VERSION ""

NS_ :

BS_:

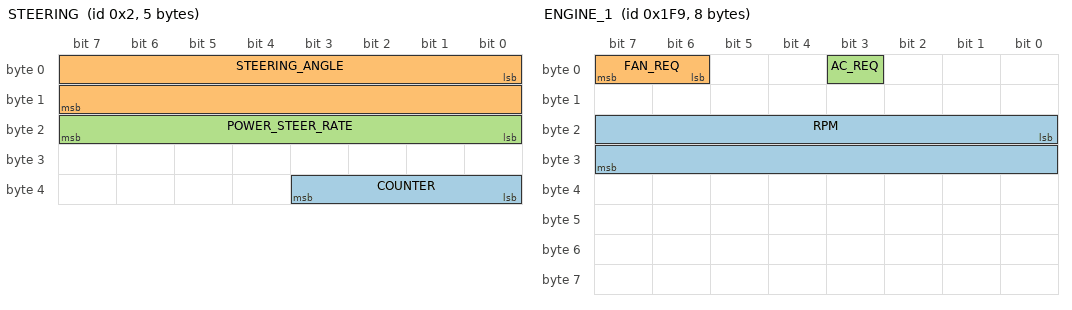
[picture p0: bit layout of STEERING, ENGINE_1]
BO_ 2 STEERING: 5 XXX
 SG_ COUNTER : 35|4@0+ (1,0) [0|255] "" XXX
 SG_ STEERING_ANGLE : 0|16@1- (0.1,0) [0|65535] "deg" XXX
 SG_ POWER_STEER_RATE : 23|8@0+ (1,0) [0|255] "" XXX

BO_ 505 ENGINE_1: 8 XXX
 SG_ RPM : 16|16@1+ (0.125,0) [0|45000] "R/min" XXX
 SG_ FAN_REQ : 6|2@1+ (1,0) [0|3] "" XXX
 SG_ AC_REQ : 3|1@1+ (1,0) [0|1] "" XXX

BO_ 561 ENGINE_2: 8 XXX
 SG_ Pedal_position : 16|8@1+ (0.5,0) [0|200] "%" XXX

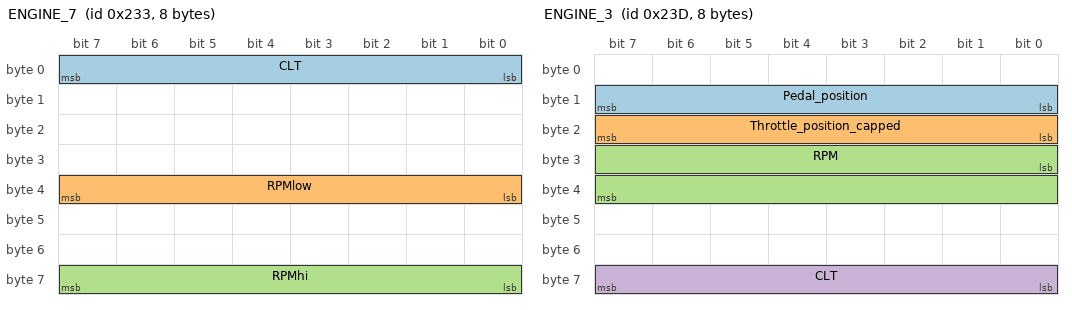
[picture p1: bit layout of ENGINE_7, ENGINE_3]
BO_ 563 ENGINE_7: 8 XXX
 SG_ CLT : 0|8@1+ (0.366666,0) [0|255] "C" XXX
 SG_ RPMlow : 32|8@1+ (3.15,0) [0|45000] "R/min" XXX
 SG_ RPMhi : 56|8@1+ (3.15,0) [0|45000] "R/min" XXX

BO_ 573 ENGINE_3: 8 XXX
 SG_ Pedal_position : 8|8@1+ (0.392,0) [0|255] "%" XXX
 SG_ Throttle_position_capped : 16|8@1+ (0.392,0) [0|255] "%" XXX
 SG_ RPM : 24|16@1+ (3.15,0) [0|45000] "R/min" XXX
 SG_ CLT : 56|8@1+ (0.366666,0) [0|255] "C" XXX

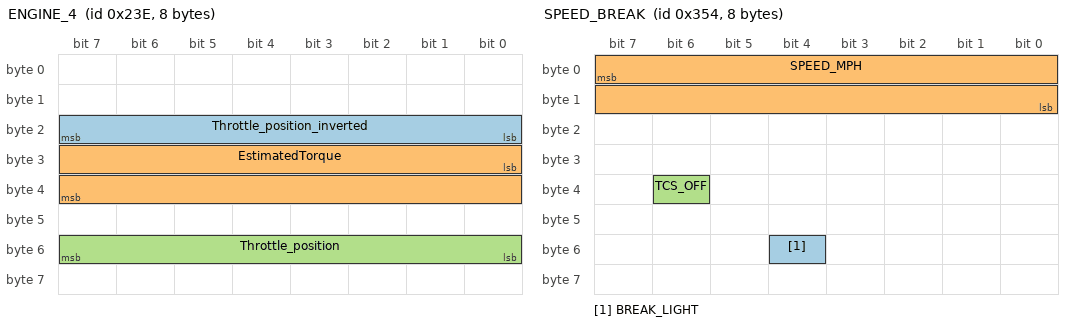
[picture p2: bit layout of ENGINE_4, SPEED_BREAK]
BO_ 574 ENGINE_4: 8 XXX
 SG_ Throttle_position_inverted : 16|8@1+ (0.392,0) [0|255] "%" XXX
 SG_ EstimatedTorque : 24|16@1+ (0.1,0) [0|45000] "nM" XXX
 SG_ Throttle_position : 48|8@1+ (0.392,0) [0|255] "%" XXX

BO_ 595 TCU_1: 8 XXX
 SG_ SHAFT_1_SPEED : 32|16@1+ (1,0) [0|45000] "r/min" XXX
 SG_ SHAFT_2_SPEED : 48|16@1+ (1,0) [0|45000] "r/min" XXX

BO_ 640 SPEED: 8 XXX
 SG_ SPEED : 32|16@1+ (0.01,0) [0|45000] "km/h" XXX

BO_ 644 ABS_1: 8 XXX
 SG_ WHEEL_1 : 0|16@1+ (0.01,0) [0|45000] "km/h" XXX
 SG_ WHEEL_2 : 15|16@1+ (0.01,0) [0|45000] "km/h" XXX

BO_ 645 ABS_2: 8 XXX
 SG_ WHEEL_3 : 0|16@1+ (0.01,0) [0|45000] "km/h" XXX
 SG_ WHEEL_4 : 15|16@1+ (0.01,0) [0|45000] "km/h" XXX

BO_ 852 SPEED_BREAK: 8 XXX
 SG_ BREAK_LIGHT : 52|1@0+ (1,0) [0|3] "" XXX
 SG_ SPEED_MPH : 7|16@0+ (0.0066,0) [0|65535] "mph" XXX
 SG_ TCS_OFF : 38|1@0+ (1,0) [0|255] "" XXX

BO_ 861 BCM: 8 XXX

BO_ 1361 ENGINE_5: 8 XXX
 SG_ CLT : 0|8@1+ (1,-45) [-45|150] "" XXX

BO_ 1408 ENGINE_6: 8 XXX
 SG_ RPM : 7|16@0+ (1.5,0) [0|65535] "" XXX
 SG_ OIL_TEMP : 32|8@1+ (1,-40) [-40|150] "" XXX

BU_: XXX

CM_ 272 "Alternative LKAS message, used on cars such as 2023 Ioniq 6, 2nd gen Kona. Matches LKAS except size is 32 bytes";
CM_ 676 "Contains signals with detailed lane line information. Used by ADAS ECU on HDA 2 vehicles to operate LFA.";
CM_ 866 "Contains signals with detailed lane line information. Used by ADAS ECU on HDA 2 vehicles to operate LFA. Used on cars that use message 272.";
CM_ 1043 "Lamp signals do not seem universal on cars that use LKAS_ALT, but stalk signals do.";

CM_ SG_ 80 HAS_LANE_SAFETY "If 0, hides LKAS 'Lane Safety' menu from vehicle settings";
CM_ SG_ 96 BRAKE_PRESSURE "User applied brake pedal pressure. Ramps from computer applied pressure on falling edge of cruise. Cruise cancels if !=0";
CM_ SG_ 101 BRAKE_POSITION "User applied brake pedal position, max is ~700. Signed on some vehicles";
CM_ SG_ 373 PROBABLY_EQUIP "aeb equip?";
CM_ SG_ 373 ACCEnable "Likely a copy of CAN's TCS13->ACCEnable";
CM_ SG_ 373 DriverBraking "Likely derived from BRAKE->BRAKE_POSITION";
CM_ SG_ 373 DriverBrakingLowSens "Higher threshold version of DriverBraking";
CM_ SG_ 352 SET_ME_9 "has something to do with AEB settings";
CM_ SG_ 416 VSetDis "set speed in display units";
CM_ SG_ 676 LEFT_LANE_LINE "Left lane line confidence";
CM_ SG_ 676 RIGHT_LANE_LINE "Right lane line confidence";
CM_ SG_ 736 MAX_SPEED "Display units. Restricts car from driving above this speed unless accelerator pedal is depressed beyond pressure point";
CM_ SG_ 866 LEFT_LANE_LINE "Left lane line confidence";
CM_ SG_ 866 RIGHT_LANE_LINE "Right lane line confidence";
CM_ SG_ 961 COUNTER_ALT "only increments on change";
CM_ SG_ 1041 COUNTER_ALT "only increments on change";
CM_ SG_ 1043 COUNTER_ALT "only increments on change";
CM_ SG_ 1043 USE_ALT_LAMP "likely 1 on cars that use alt lamp signals";
VAL_ 147 Gear_State 4 "D" 2 "N" 1 "R" 0 "P" ;
